# csi_tx_if_v2_1_VBUS2APB_WRAP_VBUSP_APB_CSI2TX_V2 register map
Vendor: Texas Instruments
Peripheral module from a debugger description file (folder J721S2).
Registers are 32-bit, read-write, reset 0x0 unless marked. A register's access mark holds for its fields unless they carry their own. Offsets are as the file gives them; lines under a group give offsets from that group; [hi:lo] are bit positions; {n}, {i} and the like mark numbered series; 'fields as' and 'values as' point back to an identical list; <NAME> marks a mode.

## csi_tx_if_v2_1_VBUS2APB_WRAP_VBUSP_APB_CSI2TX_V2
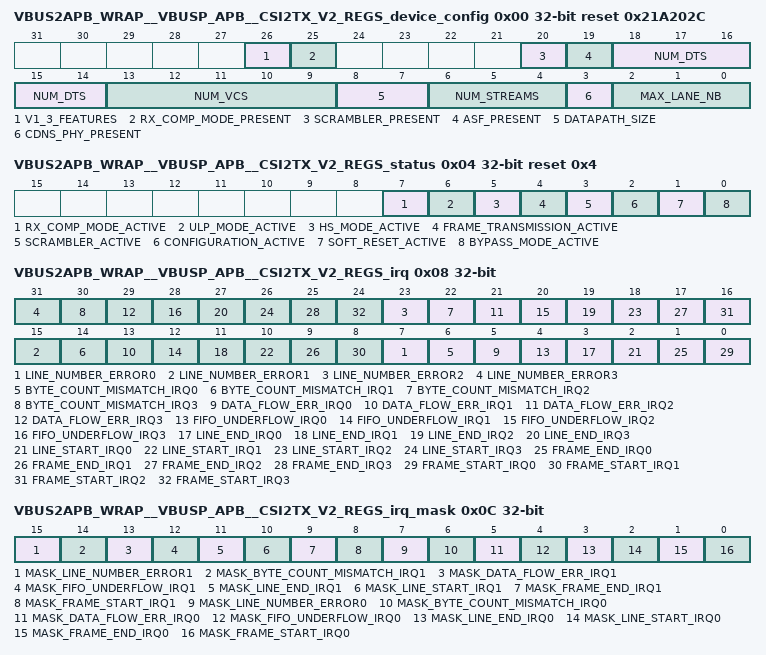
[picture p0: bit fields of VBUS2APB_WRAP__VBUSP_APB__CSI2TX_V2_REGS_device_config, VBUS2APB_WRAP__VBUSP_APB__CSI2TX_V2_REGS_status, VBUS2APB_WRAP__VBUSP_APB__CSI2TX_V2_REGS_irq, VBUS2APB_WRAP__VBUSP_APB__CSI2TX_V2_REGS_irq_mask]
0x00 VBUS2APB_WRAP__VBUSP_APB__CSI2TX_V2_REGS_device_config ro reset 0x21A202C — CSI-2 Transmitter Device Configuration Register
  [26] V1_3_FEATURES — : 1=CSI-2 v1.3 features only, 0=v2.1 features available
  [25] RX_COMP_MODE_PRESENT — RX Compatibility Mode: 1=implemented
  [20] SCRAMBLER_PRESENT — Scrambler: 1=implemented
  [19] ASF_PRESENT — Automotive Safety Features: 1=implemented
  [18:14] NUM_DTS — Number of Datatypes supported 8 or 16 only
  [13:9] NUM_VCS — Number of Virtual Channels supported 4 or 16 only
  [8:7] DATAPATH_SIZE — Internal datapath width 00: 32-bit.
  [6:4] NUM_STREAMS — Number of Stream interfaces 1, 2, or 4 only using direct encoding
  [3] CDNS_PHY_PRESENT — Cadence D-PHY present 1 = Yes
  [2:0] MAX_LANE_NB — Max Number of Lanes [1-4]
0x04 VBUS2APB_WRAP__VBUSP_APB__CSI2TX_V2_REGS_status ro reset 0x4 — CSI-2 Transmitter Status Register
  [7] RX_COMP_MODE_ACTIVE — RX Compatibility Mode Active Flag. When HIGH this bit indicates that RX Compatibility Mode is enabled.
  [6] ULP_MODE_ACTIVE — Ultra Low Power Mode Active Flag When HIGH this bit indicates that Ultra Low Power mode is active.
  [5] HS_MODE_ACTIVE — High Speed Mode Active Flag When HIGH this bit indicates that High Speed mode is active.
  [4] FRAME_TRANSMISSION_ACTIVE — Frame Transmission Active Flag When HIGH this bit indicates that frame transmission is active.
  [3] SCRAMBLER_ACTIVE — Scrambler Active Flag. When HIGH this bit indicates that the scrambler is enabled.
  [2] CONFIGURATION_ACTIVE — Configuration Mode Active Flag When HIGH this bit indicates that the CSI2TX module is in the configuration mode.
  [1] SOFT_RESET_ACTIVE — Soft Reset Active Flag When HIGH this bit indicates that soft reset is active.
  [0] BYPASS_MODE_ACTIVE — Bypass Mode Active Flag When HIGH this bit indicates that bypass mode is active.
0x08 VBUS2APB_WRAP__VBUSP_APB__CSI2TX_V2_REGS_irq access not given — CSI-2 Transmitter Interrupt Register. Write '1' to clear
  [8n+7] LINE_NUMBER_ERROR{n} (n=0..3) — Pixel IF {n} Line Number Error Flag - When HIGH this bit indicates that a line number error occurred. (access R/W1TC)
  [8n+6] BYTE_COUNT_MISMATCH_IRQ{n} (n=0..3) — Pixel IF {n} Byte Count Mismatch Flag - When HIGH this bit indicates that a byte count mismatch occurred. (access R/W1TC)
  [8n+5] DATA_FLOW_ERR_IRQ{n} (n=0..3) — Pixel IF {n} Data Flow Error Flag - When HIGH this bit indicates that data flow error has occurred, caused by the Frame/Line valid being asserted when the D-PHY is not ready. (access R/W1TC)
  [8n+4] FIFO_UNDERFLOW_IRQ{n} (n=0..3) — Pixel IF {n} FIFO Underflow Flag - When HIGH this bit indicates that at least one internal FIFO underflow occurred. (access R/W1TC)
  [8n+3] LINE_END_IRQ{n} (n=0..3) — Pixel IF {n} Line End Flag - When HIGH this bit indicates that a line end occurred. (access R/W1TC)
  [8n+2] LINE_START_IRQ{n} (n=0..3) — Pixel IF {n} Line Start Flag - When HIGH this bit indicates that a line start occurred. (access R/W1TC)
  [8n+1] FRAME_END_IRQ{n} (n=0..3) — Pixel IF {n} Frame End Flag - When HIGH this bit indicates that a frame end occurred. (access R/W1TC)
  [8n] FRAME_START_IRQ{n} (n=0..3) — Pixel IF {n} Frame Start Flag - When HIGH this bit indicates that a frame start occurred. (access R/W1TC)
0x0C VBUS2APB_WRAP__VBUSP_APB__CSI2TX_V2_REGS_irq_mask — CSI-2 Transmitter Interrupt Mask Register. In ASF configurations this register is parity protected.
  [15] MASK_LINE_NUMBER_ERROR1 — Pixel IF 1 Line Number Error Mask - Writing 1 to this bit enables interrupt generation from the line_number_error_irq bit.
  [14] MASK_BYTE_COUNT_MISMATCH_IRQ1 — Pixel IF 1 Byte Count Mismatch Mask - Writing 1 to this bit enables interrupt generation from the byte_count_mismatch_irq bit.
  [13] MASK_DATA_FLOW_ERR_IRQ1 — Pixel IF 1 Data Flow Error Mask - Writing 1 to this bit enables interrupt generation from the data_flow_err_irq bit.
  [12] MASK_FIFO_UNDERFLOW_IRQ1 — Pixel IF 1 FIFO Underflow Mask - Writing 1 to this bit enables interrupt generation from the fifo_underflow_irq bit.
  [11] MASK_LINE_END_IRQ1 — Pixel IF 1 Line End Mask - Writing 1 to this bit enables interrupt generation from the line_en_irq bit.
  [10] MASK_LINE_START_IRQ1 — Pixel IF 1 Line Start Mask - Writing 1 to this bit enables interrupt generation from the line_start_irq bit.
  [9] MASK_FRAME_END_IRQ1 — Pixel IF 1 Frame End Mask - Writing 1 to this bit enables interrupt generation from the frame_end_irq bit.
  [8] MASK_FRAME_START_IRQ1 — Pixel IF 1 Frame Start Mask - Writing 1 to this bit enables interrupt generation from the frame_start_irq bit.
  [7] MASK_LINE_NUMBER_ERROR0 — Pixel IF 0 Line Number Error Mask - Writing 1 to this bit enables interrupt generation from the line_number_error_irq bit.
  [6] MASK_BYTE_COUNT_MISMATCH_IRQ0 — Pixel IF 0 Byte Count Mismatch Mask - Writing 1 to this bit enables interrupt generation from the byte_count_mismatch_irq bit.
  [5] MASK_DATA_FLOW_ERR_IRQ0 — Pixel IF 0 Data Flow Error Mask - Writing 1 to this bit enables interrupt generation from the data_flow_err_irq bit.
  [4] MASK_FIFO_UNDERFLOW_IRQ0 — Pixel IF 0 FIFO Underflow Mask - Writing 1 to this bit enables interrupt generation from the fifo_underflow_irq bit.
  [3] MASK_LINE_END_IRQ0 — Pixel IF 0 Line End Mask - Writing 1 to this bit enables interrupt generation from the line_en_irq bit.
  [2] MASK_LINE_START_IRQ0 — Pixel IF 0 Line Start Mask - Writing 1 to this bit enables interrupt generation from the line_start_irq bit.
  [1] MASK_FRAME_END_IRQ0 — Pixel IF 0 Frame End Mask - Writing 1 to this bit enables interrupt generation from the frame_end_irq bit.
  [0] MASK_FRAME_START_IRQ0 — Pixel IF 0 Frame Start Mask - Writing 1 to this bit enables interrupt generation from the frame_start_irq bit.
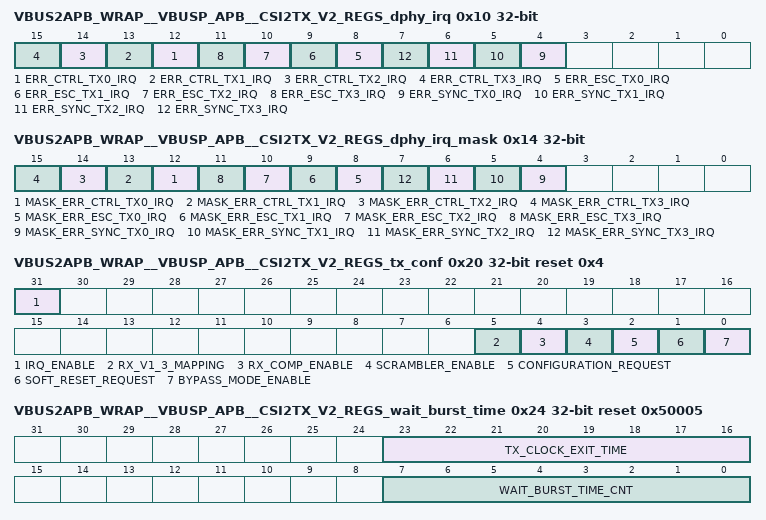
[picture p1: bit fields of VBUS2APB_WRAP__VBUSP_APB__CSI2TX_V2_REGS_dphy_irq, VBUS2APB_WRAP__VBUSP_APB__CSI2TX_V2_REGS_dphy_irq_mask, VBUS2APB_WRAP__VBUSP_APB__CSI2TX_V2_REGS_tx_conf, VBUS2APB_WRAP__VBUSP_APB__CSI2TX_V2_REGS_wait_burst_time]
0x10 VBUS2APB_WRAP__VBUSP_APB__CSI2TX_V2_REGS_dphy_irq access not given — D-PHY Transmitter Interrupt Status. Level sensitive interrupt bits driven by D-PHY signal pins. Write 1 to clear
  [n+12] ERR_CTRL_TX{n}_IRQ (n=0..3) — D-PHY Transmitter Lane {n} ERR_CONTROL_IRQ (access R/W1TC)
  [n+8] ERR_ESC_TX{n}_IRQ (n=0..3) — D-PHY Transmitter Lane {n} ERR_ESC_IRQ (access R/W1TC)
  [n+4] ERR_SYNC_TX{n}_IRQ (n=0..3) — D-PHY Transmitter Lane {n} ERR_SYNC_ESC_IRQ (access R/W1TC)
0x14 VBUS2APB_WRAP__VBUSP_APB__CSI2TX_V2_REGS_dphy_irq_mask — D-PHY Transmitter Interrupt Mask. Writing '1' to any bit enables interrupt generation when interrupt source signal is set and interrupts are enabled. In ASF configurations this register is parity protected.
  [n+12] MASK_ERR_CTRL_TX{n}_IRQ (n=0..3) — D-PHY Transmitter Mask Lane {n} ERR_CONTROL_IRQ
  [n+8] MASK_ERR_ESC_TX{n}_IRQ (n=0..3) — D-PHY Transmitter Mask Lane {n} ERR_ESC_IRQ
  [n+4] MASK_ERR_SYNC_TX{n}_IRQ (n=0..3) — D-PHY Transmitter Mask Lane {n} ERR_SYNC_ESC_IRQ
0x20 VBUS2APB_WRAP__VBUSP_APB__CSI2TX_V2_REGS_tx_conf reset 0x4 — CSI-2 Transmitter Configuration Register. In ASF configurations this register is parity protected.
  [31] IRQ_ENABLE — Interrupt Enable - Writing 1 to this bit enables interrupts.
  [5] RX_V1_3_MAPPING — RX v1.3 Mapping Enable - Writing 1 to this bit make the TX Controller use pixel mappings for 8-bit data types which match that of the Cadence CSI-2 RX v1.3 Controller. This includes RAW8, Null, Blanking, Embedded, User Defined and Generic Long Packet data types. This bit is only available if RX_COMP_MODE is configured.
  [4] RX_COMP_ENABLE — RX Compatibility Mode Enable - Writing 1 to this bit enables RX Compatibility Mode.
  [3] SCRAMBLER_ENABLE — Scrambler Enable - Writing 1 to this bit enables scrambling on the ppi tx data bus.
  [2] CONFIGURATION_REQUEST — Configuration Request - Writing 1 to this bit enables configuration mode.
  [1] SOFT_RESET_REQUEST — Soft Reset Request - Writing 1 to this bit enables soft reset.
  [0] BYPASS_MODE_ENABLE — Bypass Mode - Enable Writing 1 to this bit enables bypass mode.
0x24 VBUS2APB_WRAP__VBUSP_APB__CSI2TX_V2_REGS_wait_burst_time reset 0x50005 — CSI-2 Transmitter D-PHY Wait Time Configuration Register. In ASF configurations this register is parity protected.
  [23:16] TX_CLOCK_EXIT_TIME — Tx clock exit time - Number of ppi_tx_word_hs_clk cycles corresponding to the HS clock exit time.
  [7:0] WAIT_BURST_TIME_CNT — Wait Burst Time - Number of ppi_tx_word_hs_clk cycles corresponding to the inter HS burst gap.
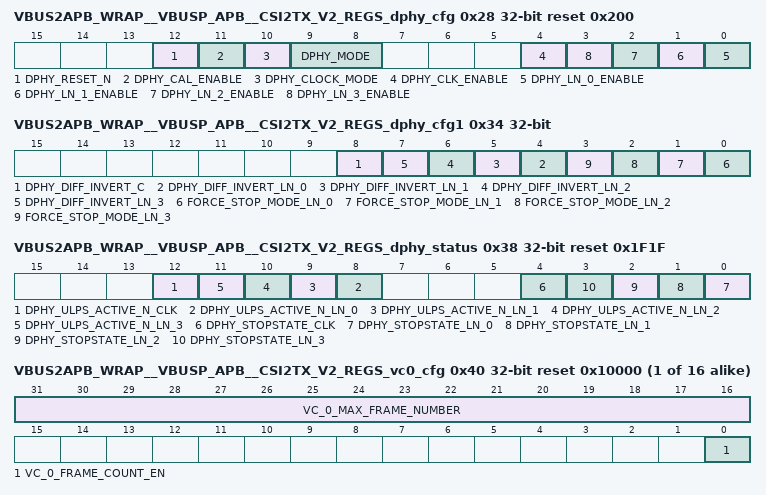
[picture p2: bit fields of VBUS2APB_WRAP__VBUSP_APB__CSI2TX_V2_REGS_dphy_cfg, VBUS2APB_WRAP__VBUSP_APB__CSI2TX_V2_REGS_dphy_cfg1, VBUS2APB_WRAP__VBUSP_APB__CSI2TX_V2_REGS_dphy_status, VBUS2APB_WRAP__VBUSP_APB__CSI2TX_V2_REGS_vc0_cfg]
0x28 VBUS2APB_WRAP__VBUSP_APB__CSI2TX_V2_REGS_dphy_cfg reset 0x200 — CSI-2 Transmitter D-PHY Lane Enable Configuration Register. In ASF configurations this register is parity protected.
  [12] DPHY_RESET_N — D-PHY Reset - Active low reset for D-PHY.
  [11] DPHY_CAL_ENABLE — D-PHY Calibration Enable. Enables calibration for D-PHY speeds over 1.5G.
  [10] DPHY_CLOCK_MODE — D-PHY Clock Mode. Select the D-PHY Clock Lane mode 0: Continuous 1: Non Continuous
  [9:8] DPHY_MODE — D-PHY Mode. Select the D-PHY clock mode during Non Continuous operation 00: Ultra Low Power 01: High Speed 10: Low Power Stop State 11: Reserved
  [4] DPHY_CLK_ENABLE — D-PHY Clock Lane - Active high enable for D-PHY clock lane.
  [n] DPHY_LN_{n}_ENABLE (n=0..3) — D-PHY Lane {n} Enable - Active high enable for D-PHY data lane 0.
0x2C VBUS2APB_WRAP__VBUSP_APB__CSI2TX_V2_REGS_dphy_clk_wakeup reset 0x4E20 — CSI-2 Transmitter D-PHY Clock Lane Wakeup Time Configuration Register. In ASF configurations this register is parity protected.
  [15:0] ULPS_CLK_LANE_WAKEUP — D-PHY clock lane wakeup time in ppi_tx_esc_clk cycles.
0x30 VBUS2APB_WRAP__VBUSP_APB__CSI2TX_V2_REGS_dphy_ulps_wakeup reset 0x4E20 — CSI-2 Transmitter D-PHY Data Lane Wakeup Time Configuration Register. In ASF configurations this register is parity protected.
  [15:0] ULPS_DATA_LANE_WAKEUP — D-PHY data lane wakeup time in in ppi_tx_esc_clk cycles.
0x34 VBUS2APB_WRAP__VBUSP_APB__CSI2TX_V2_REGS_dphy_cfg1 — D-PHY Transmitter Configuration. In ASF configurations this register is parity protected.
  [8] DPHY_DIFF_INVERT_C — D-PHY Transmitter invert differential pair on TX Clock Lane
  [n+4] DPHY_DIFF_INVERT_LN_{n} (n=0..3) — D-PHY Transmitter invert differential pair on TX Data Lane {n}.
  [n] FORCE_STOP_MODE_LN_{n} (n=0..3) — D-PHY Transmitter FORCE_STOP_MODE TX Data Lane {n}.
0x38 VBUS2APB_WRAP__VBUSP_APB__CSI2TX_V2_REGS_dphy_status ro reset 0x1F1F — D-PHY Transmitter Status.
  [12] DPHY_ULPS_ACTIVE_N_CLK — D-PHY Transmitter ULPS_ACTIVE_N Clock Lane Status.
  [n+8] DPHY_ULPS_ACTIVE_N_LN_{n} (n=0..3) — D-PHY Transmitter ULPS_ACTIVE_N Data Lane {n} Status.
  [4] DPHY_STOPSTATE_CLK — D-PHY Transmitter STOP_STATE Clock Lane Status.
  [n] DPHY_STOPSTATE_LN_{n} (n=0..3) — D-PHY Transmitter STOP_STATE Data Lane {n} Status.
{0x40+4i} VBUS2APB_WRAP__VBUSP_APB__CSI2TX_V2_REGS_vc{i}_cfg reset 0x10000 (i=0..15) — CSI-2 Transmitter Virtual Channel {i} Configuration Register. In ASF configurations this register is parity protected.
  [31:16] VC_{i}_MAX_FRAME_NUMBER — Max Frame Number - Maximum number of frames on Virtual Channel {i}.
  [0] VC_{i}_FRAME_COUNT_EN — Frame Count Enable - Writing 1 to this bit enables frame count on Virtual Channel {i}.
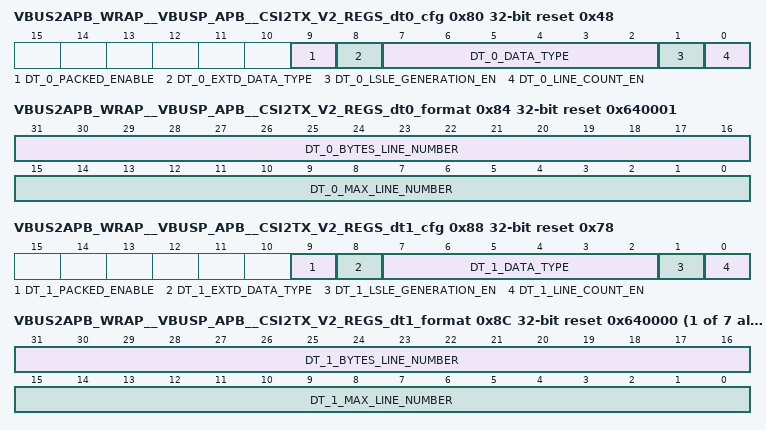
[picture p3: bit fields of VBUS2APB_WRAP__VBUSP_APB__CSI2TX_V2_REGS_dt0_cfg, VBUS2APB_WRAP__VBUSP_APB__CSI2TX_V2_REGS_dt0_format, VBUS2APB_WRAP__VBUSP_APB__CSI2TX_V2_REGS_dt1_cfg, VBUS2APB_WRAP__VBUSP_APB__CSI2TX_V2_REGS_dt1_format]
0x80 VBUS2APB_WRAP__VBUSP_APB__CSI2TX_V2_REGS_dt0_cfg reset 0x48 — CSI-2 Transmitter Data Type 0 Configuration Register with pixel_dt_sel[:] = 0. In ASF configurations this register is parity protected.
  [9] DT_0_PACKED_ENABLE — Packed Enable - data stream is prepacked in to 32-bit words on the pixel interface, the data is sent with the defined Data Type 0 with pixel_dt_sel[:] = 0. This bit is also used for quad pixel 8-bit data types.
  [8] DT_0_EXTD_DATA_TYPE — Extended Data Type - Type of data on Data Type 0 with pixel_dt_sel[:] = 0.
  [7:2] DT_0_DATA_TYPE — Data Type - Type of data on Data Type 0 with pixel_dt_sel[:] = 0. Default ED [0x12]
  [1] DT_0_LSLE_GENERATION_EN — Line Start And Line End Short Packet Generation Enable - Writing 1 to this bit enables Line Start and Line End generation on Data Type 0.
  [0] DT_0_LINE_COUNT_EN — Line Count Enable - Writing 1 to this bit enables line count on Data Type 0.
0x84 VBUS2APB_WRAP__VBUSP_APB__CSI2TX_V2_REGS_dt0_format reset 0x640001 — CSI-2 Transmitter Data Type 0 Format Register. In ASF configurations this register is parity protected.
  [31:16] DT_0_BYTES_LINE_NUMBER — Bytes Per Line - Bytes per line on Data Type 0 with pixel_dt_sel[:] = 0.
  [15:0] DT_0_MAX_LINE_NUMBER — Max Line Number - Maximum number of lines on Data Type 0 with pixel_dt_sel[:] = 0.
0x88 VBUS2APB_WRAP__VBUSP_APB__CSI2TX_V2_REGS_dt1_cfg reset 0x78 — CSI-2 Transmitter Data Type 1 Configuration Register with pixel_dt_sel[:] = 1. In ASF configurations this register is parity protected.
  [9] DT_1_PACKED_ENABLE — Packed Enable - data stream is prepacked in to 32-bit words on the pixel interface, the data is sent with the defined Data Type 1 with pixel_dt_sel[:] = 1. This bit is also used for quad pixel 8-bit data types.
  [8] DT_1_EXTD_DATA_TYPE — Extended Data Type - Type of data on Data Type 1 with pixel_dt_sel[:] = 1.
  [7:2] DT_1_DATA_TYPE — Data Type - Type of data on Data Type 1 with pixel_dt_sel[:] = 1. Default YUV422 8bit [0x1E]
  [1] DT_1_LSLE_GENERATION_EN — Line Start And Line End Short Packet Generation Enable - Writing 1 to this bit enables Line Start and Line End generation on Data Type 1.
  [0] DT_1_LINE_COUNT_EN — Line Count Enable - Writing 1 to this bit enables line count on Data Type 1.
{0x84+8i} VBUS2APB_WRAP__VBUSP_APB__CSI2TX_V2_REGS_dt{i}_format reset 0x640000 (i=1..7) — CSI-2 Transmitter Data Type {i} Format Register. In ASF configurations this register is parity protected.
  [31:16] DT_{i}_BYTES_LINE_NUMBER — Bytes Per Line - Bytes per line on Data Type {i} with pixel_dt_sel[:] = {i}.
  [15:0] DT_{i}_MAX_LINE_NUMBER — Max Line Number - Maximum number of lines on Data Type {i} with pixel_dt_sel[:] = {i}.
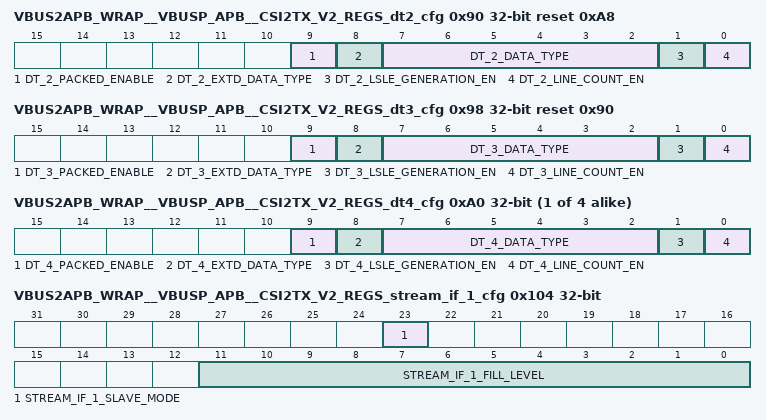
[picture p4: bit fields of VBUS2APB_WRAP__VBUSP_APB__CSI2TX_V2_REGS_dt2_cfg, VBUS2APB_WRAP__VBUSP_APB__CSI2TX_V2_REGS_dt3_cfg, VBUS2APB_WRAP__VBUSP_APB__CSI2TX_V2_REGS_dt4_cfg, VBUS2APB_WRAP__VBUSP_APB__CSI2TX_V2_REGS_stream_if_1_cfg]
0x90 VBUS2APB_WRAP__VBUSP_APB__CSI2TX_V2_REGS_dt2_cfg reset 0xA8 — CSI-2 Transmitter Data Type 2 Configuration Register with pixel_dt_sel[:] = 2. In ASF configurations this register is parity protected.
  [9] DT_2_PACKED_ENABLE — Packed Enable - data stream is prepacked in to 32-bit words on the pixel interface, the data is sent with the defined Data Type 2 with pixel_dt_sel[:] = 2. This bit is also used for quad pixel 8-bit data types.
  [8] DT_2_EXTD_DATA_TYPE — Extended Data Type - Type of data on Data Type 2 with pixel_dt_sel[:] = 2.
  [7:2] DT_2_DATA_TYPE — Data Type - Type of data on Data Type 2 with pixel_dt_sel[:] = 2. Default RAW8 [0x2A]
  [1] DT_2_LSLE_GENERATION_EN — Line Start And Line End Short Packet Generation Enable - Writing 1 to this bit enables Line Start and Line End generation on Data Type 2.
  [0] DT_2_LINE_COUNT_EN — Line Count Enable - Writing 1 to this bit enables line count on Data Type 2.
0x98 VBUS2APB_WRAP__VBUSP_APB__CSI2TX_V2_REGS_dt3_cfg reset 0x90 — CSI-2 Transmitter Data Type 3 Configuration Register with pixel_dt_sel[:] = 3. In ASF configurations this register is parity protected.
  [9] DT_3_PACKED_ENABLE — Packed Enable - data stream is prepacked in to 32-bit words on the pixel interface, the data is sent with the defined Data Type 3 with pixel_dt_sel[:] = 3. This bit is also used for quad pixel 8-bit data types.
  [8] DT_3_EXTD_DATA_TYPE — Extended Data Type - Type of data on Data Type 3 with pixel_dt_sel[:] = 3.
  [7:2] DT_3_DATA_TYPE — Data Type - Type of data on Data Type 3 with pixel_dt_sel[:] = 3. Default RGB888 [0x24]
  [1] DT_3_LSLE_GENERATION_EN — Line Start And Line End Short Packet Generation Enable - Writing 1 to this bit enables Line Start and Line End generation on Data Type 3.
  [0] DT_3_LINE_COUNT_EN — Line Count Enable - Writing 1 to this bit enables line count on Data Type 3.
{0x80+8i} VBUS2APB_WRAP__VBUSP_APB__CSI2TX_V2_REGS_dt{i}_cfg (i=4..7) — CSI-2 Transmitter Data Type {i} Configuration Register with pixel_dt_sel[:] = {i}. In ASF configurations this register is parity protected.
  [9] DT_{i}_PACKED_ENABLE — Packed Enable - data stream is prepacked in to 32-bit words on the pixel interface, the data is sent with the defined Data Type {i} with pixel_dt_sel[:] = {i}. This bit is also used for quad pixel 8-bit data types.
  [8] DT_{i}_EXTD_DATA_TYPE — Extended Data Type - Type of data on Data Type {i} with pixel_dt_sel[:] = {i}.
  [7:2] DT_{i}_DATA_TYPE — Data Type - Type of data on Data Type {i} with pixel_dt_sel[:] = {i}.
  [1] DT_{i}_LSLE_GENERATION_EN — Line Start And Line End Short Packet Generation Enable - Writing 1 to this bit enables Line Start and Line End generation on Data Type {i}.
  [0] DT_{i}_LINE_COUNT_EN — Line Count Enable - Writing 1 to this bit enables line count on Data Type {i}.
0x100 VBUS2APB_WRAP__VBUSP_APB__CSI2TX_V2_REGS_stream_if_0_cfg — CSI-2 Stream 0 Configuration Register. In ASF configurations this register is parity protected.
  [11:0] STREAM_IF_0_FILL_LEVEL — Fill Level - Minimum number of packed 32 words loaded into the stream fifo before Tx will start for Stream if 0.
0x104 VBUS2APB_WRAP__VBUSP_APB__CSI2TX_V2_REGS_stream_if_1_cfg — CSI-2 Stream 1 Configuration Register. In ASF configurations this register is parity protected.
  [23] STREAM_IF_1_SLAVE_MODE — Stream Slave Mode suppresses frame start/end packets in stream 1. To be used when DT interleving is required in the same VC. NOTE: the stream must then be paired with stream O as the master on the StreamIF
  [11:0] STREAM_IF_1_FILL_LEVEL — Fill Level - Minimum number of packed 32 words loaded into the stream fifo before Tx will start for Stream if 1.
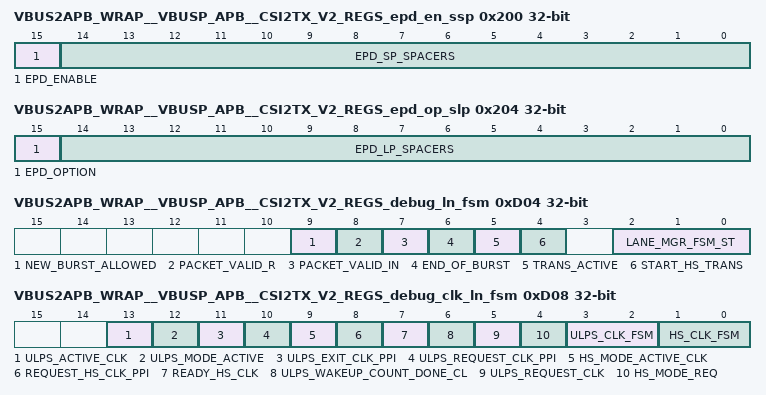
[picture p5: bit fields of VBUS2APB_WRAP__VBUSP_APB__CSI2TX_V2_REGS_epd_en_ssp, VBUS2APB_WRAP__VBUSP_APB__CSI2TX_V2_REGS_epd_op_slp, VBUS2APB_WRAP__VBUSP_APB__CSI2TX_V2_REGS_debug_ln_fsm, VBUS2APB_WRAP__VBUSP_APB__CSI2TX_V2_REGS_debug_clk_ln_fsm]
0x200 VBUS2APB_WRAP__VBUSP_APB__CSI2TX_V2_REGS_epd_en_ssp — CSI-2 Transmitter EPD Enable and Short Packet Spacers Register Mandatory register in the CSI-2 v2.x specification. In ASF configurations this register is parity protected.
  [15] EPD_ENABLE — EPD enable. Set high to enable EPD operation.
  [14:0] EPD_SP_SPACERS — EPD Short Packet Spacers: EPD Option 1: Minimum number of Spacer Bytes per Lane following a Short Packet. EPD Option 2: Fixed number of Spacer Bytes per Lane following a Short Packet.
0x204 VBUS2APB_WRAP__VBUSP_APB__CSI2TX_V2_REGS_epd_op_slp — CSI-2 Transmitter EPD Option and Long Packet Spacers Register Mandatory register in the CSI-2 v2.x specification. In ASF configurations this register is parity protected.
  [15] EPD_OPTION — EPD Option. 1'b0: D-PHY EPD Option 1 1'b1: D-PHY EPD Option 2
  [14:0] EPD_LP_SPACERS — EPD Long Packet Spacers: EPD Option 1: Minimum number of Spacer Bytes per Lane following a Long Packet. EPD Option 2: Fixed number of Spacer Bytes per Lane following a Long Packet.
0x208 VBUS2APB_WRAP__VBUSP_APB__CSI2TX_V2_REGS_epd_clkidlehs_min reset 0x10 — CSI-2 Transmitter EPD Minimum HS Clock Idle Time Register In ASF configurations this register is parity protected.
  [15:0] EPD_OPTION1_CLKIDLEHS_MIN — For LRTE EPD Option 1, this sets the minimum number of pclk cycles required to meet the D-PHY timing requirement for THS-IDLE-CLKHS0.
0xD00 VBUS2APB_WRAP__VBUSP_APB__CSI2TX_V2_REGS_debug_cfg — CSI-2 Transmitter Debug Enable Register. In ASF configurations this register is parity protected.
  [0] DBG_EN — Debug Enable. This bit enables debug when high. If low then other DEBUG registers read 0.
0xD04 VBUS2APB_WRAP__VBUSP_APB__CSI2TX_V2_REGS_debug_ln_fsm ro — Debug Register for Lane FSM.
  [9] NEW_BURST_ALLOWED — Lane Mangement FSM. New burst allowed - WAIT_BURST_TIME expired
  [8] PACKET_VALID_R — Lane Mangement FSM. Valid packet in packet register
  [7] PACKET_VALID_IN — Lane Mangement FSM. Valid packet at input
  [6] END_OF_BURST — Lane Mangement FSM. End of High speed burst
  [5] TRANS_ACTIVE — Lane Mangement FSM. HS transmission active
  [4] START_HS_TRANS — Lane Mangement FSM. HS transmission ready
  [2:0] LANE_MGR_FSM_ST — Lane Mangement FSM. State of Lane Management FSM
0xD08 VBUS2APB_WRAP__VBUSP_APB__CSI2TX_V2_REGS_debug_clk_ln_fsm ro — Debug Register for Clock Lane FSM
  [13] ULPS_ACTIVE_CLK — Clock Lane FSM. ULPS active from D-PHY
  [12] ULPS_MODE_ACTIVE — Clock Lane FSM. ULPS mode active
  [11] ULPS_EXIT_CLK_PPI — Clock Lane FSM. ULPS EXIT Request to D-PHY
  [10] ULPS_REQUEST_CLK_PPI — Clock Lane FSM. ULPS request to D-PHY
  [9] HS_MODE_ACTIVE_CLK — Clock Lane FSM. High speed mode active
  [8] REQUEST_HS_CLK_PPI — Clock Lane FSM. High speed clock request
  [7] READY_HS_CLK — Clock Lane FSM. High speed clock active from D-PHY
  [6] ULPS_WAKEUP_COUNT_DONE_CL — Clock Lane FSM. Clock lane ULPS wakeup counter expired
  [5] ULPS_REQUEST_CLK — Clock Lane FSM. Request ULPS mode
  [4] HS_MODE_REQ — Clock Lane FSM. Request High Speed mode
  [3:2] ULPS_CLK_FSM — Clock Lane FSM. State of ULPS control FSM.
  [1:0] HS_CLK_FSM — Clock Lane FSM. State of High Speed Clock FSM.
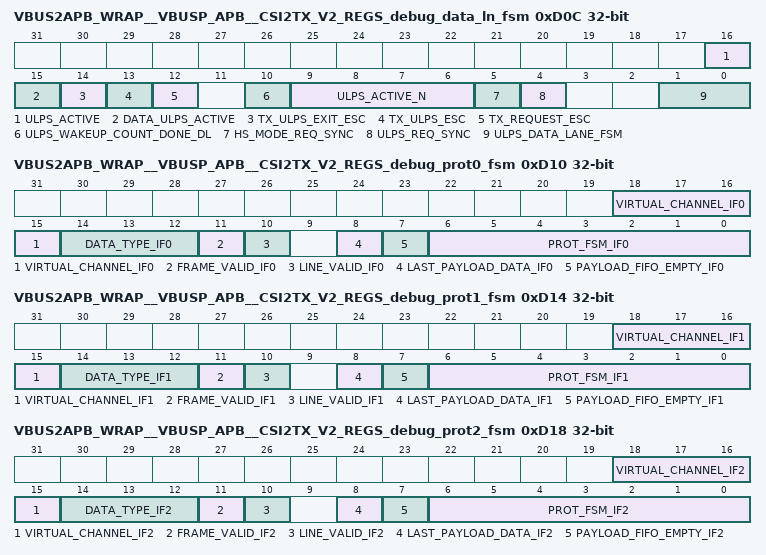
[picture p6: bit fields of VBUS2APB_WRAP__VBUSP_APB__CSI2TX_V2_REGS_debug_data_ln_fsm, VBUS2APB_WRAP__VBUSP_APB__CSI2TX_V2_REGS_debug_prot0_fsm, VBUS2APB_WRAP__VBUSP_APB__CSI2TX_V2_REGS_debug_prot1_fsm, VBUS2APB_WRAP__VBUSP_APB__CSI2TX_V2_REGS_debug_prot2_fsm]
0xD0C VBUS2APB_WRAP__VBUSP_APB__CSI2TX_V2_REGS_debug_data_ln_fsm ro — Debug Register for Data Lane FSM.
  [16] ULPS_ACTIVE — Data Lane FSM. Clock and data lane ULPS active
  [15] DATA_ULPS_ACTIVE — Debug Register for Data Lane FSM. Data lane ULPS active
  [14] TX_ULPS_EXIT_ESC — Data Lane FSM. Exit escape mode to D-PHY
  [13] TX_ULPS_ESC — Data Lane FSM. ULPS escape mode to D-PHY
  [12] TX_REQUEST_ESC — Data Lane FSM. Request escape mode to D-PHY
  [10] ULPS_WAKEUP_COUNT_DONE_DL — Data Lane FSM. Data Lane ULPS wakeup counter expired
  [9:6] ULPS_ACTIVE_N — Data Lane FSM. Data Lane ULPS active from D-PHY
  [5] HS_MODE_REQ_SYNC — Data Lane FSM. HS Mode request
  [4] ULPS_REQ_SYNC — Data Lane FSM. ULPS Request
  [1:0] ULPS_DATA_LANE_FSM — Data Lane FSM. State of Data Lane FSM FSM
0xD10 VBUS2APB_WRAP__VBUSP_APB__CSI2TX_V2_REGS_debug_prot0_fsm ro — Debug Register for Pixel IF0 Protocol FSM.
  [18:15] VIRTUAL_CHANNEL_IF0 — Pixel IF0 Protocol FSM. State of the top level Virtual Channel select signals State of the Virtual Channel[3:2] select signals when VCX enabled, otherwise '00' and state of the Virtual Channel[1:0]
  [14:12] DATA_TYPE_IF0 — Pixel IF0 Protocol FSM. State of the Data Type select signals
  [11] FRAME_VALID_IF0 — Pixel IF0 Protocol FSM. State of the Frame Valid signal
  [10] LINE_VALID_IF0 — Pixel IF0 Protocol FSM. State of the Line Valid signal
  [8] LAST_PAYLOAD_DATA_IF0 — Pixel IF0 Protocol FSM. Last payload data in long packet
  [7] PAYLOAD_FIFO_EMPTY_IF0 — Pixel IF0 Protocol FSM. Payload FIFO empty
  [6:0] PROT_FSM_IF0 — Pixel IF0 Protocol FSM. State of Protocol Control FSM
0xD14 VBUS2APB_WRAP__VBUSP_APB__CSI2TX_V2_REGS_debug_prot1_fsm ro — Debug Register for Pixel IF1 Protocol FSM. (Optional: Available when PIXEL_IF2 or 4)
  [18:15] VIRTUAL_CHANNEL_IF1 — Pixel IF1 Protocol FSM. State of the top level Virtual Channel select signals State of the Virtual Channel[3:2] select signals when VCX enabled, otherwise '00' and state of the Virtual Channel[1:0]
  [14:12] DATA_TYPE_IF1 — Pixel IF1 Protocol FSM. State of the Data Type select signals
  [11] FRAME_VALID_IF1 — Pixel IF1 Protocol FSM. State of the Frame Valid signal
  [10] LINE_VALID_IF1 — Pixel IF1 Protocol FSM. State of the Line Valid signal
  [8] LAST_PAYLOAD_DATA_IF1 — Pixel IF1 Protocol FSM. Last payload data in long packet
  [7] PAYLOAD_FIFO_EMPTY_IF1 — Pixel IF1 Protocol FSM. Payload FIFO empty
  [6:0] PROT_FSM_IF1 — Pixel IF1 Protocol FSM. State of Protocol Control FSM
0xD18 VBUS2APB_WRAP__VBUSP_APB__CSI2TX_V2_REGS_debug_prot2_fsm ro — Debug Register for Pixel IF2 Protocol FSM. (Optional: Available when PIXEL_IF4)
  [18:15] VIRTUAL_CHANNEL_IF2 — Pixel IF2 Protocol FSM. State of the top level Virtual Channel select signals State of the Virtual Channel[3:2] select signals when VCX enabled, otherwise '00' and state of the Virtual Channel[1:0]
  [14:12] DATA_TYPE_IF2 — Pixel IF2 Protocol FSM. State of the Data Type select signals
  [11] FRAME_VALID_IF2 — Pixel IF2 Protocol FSM. State of the Frame Valid signal
  [10] LINE_VALID_IF2 — Pixel IF2 Protocol FSM. State of the Line Valid signal
  [8] LAST_PAYLOAD_DATA_IF2 — Pixel IF2 Protocol FSM. Last payload data in long packet
  [7] PAYLOAD_FIFO_EMPTY_IF2 — Pixel IF2 Protocol FSM. Payload FIFO empty
  [6:0] PROT_FSM_IF2 — Pixel IF2 Protocol FSM. State of Protocol Control FSM
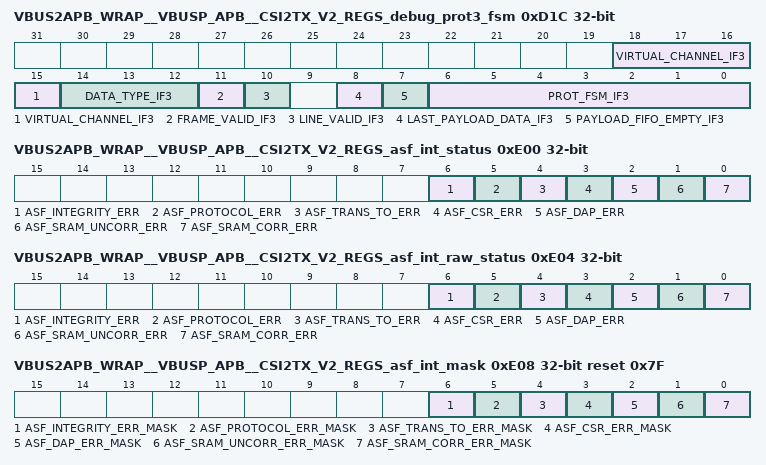
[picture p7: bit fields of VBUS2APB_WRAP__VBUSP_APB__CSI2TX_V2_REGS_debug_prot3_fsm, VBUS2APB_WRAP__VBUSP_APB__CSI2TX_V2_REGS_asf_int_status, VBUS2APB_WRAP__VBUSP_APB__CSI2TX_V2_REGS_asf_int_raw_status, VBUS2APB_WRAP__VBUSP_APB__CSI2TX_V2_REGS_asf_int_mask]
0xD1C VBUS2APB_WRAP__VBUSP_APB__CSI2TX_V2_REGS_debug_prot3_fsm ro — Debug Register for Pixel IF3 Protocol FSM. (Optional: Available when PIXEL_IF4)
  [18:15] VIRTUAL_CHANNEL_IF3 — Pixel IF3 Protocol FSM. State of the top level Virtual Channel select signals State of the Virtual Channel[3:2] select signals when VCX enabled, otherwise '00' and state of the Virtual Channel[1:0]
  [14:12] DATA_TYPE_IF3 — Pixel IF3 Protocol FSM. State of the Data Type select signals
  [11] FRAME_VALID_IF3 — Pixel IF3 Protocol FSM. State of the Frame Valid signal
  [10] LINE_VALID_IF3 — Pixel IF3 Protocol FSM. State of the Line Valid signal
  [8] LAST_PAYLOAD_DATA_IF3 — Pixel IF3 Protocol FSM. Last payload data in long packet
  [7] PAYLOAD_FIFO_EMPTY_IF3 — Pixel IF3 Protocol FSM. Payload FIFO empty
  [6:0] PROT_FSM_IF3 — Pixel IF3 Protocol FSM. State of Protocol Control FSM
0xDF8 VBUS2APB_WRAP__VBUSP_APB__CSI2TX_V2_REGS_test_generic_status ro — GPIO - Generic test status register that read primary inputs: test_generic_status
  [15:0] STATUS — Test status - Directly reflects, after resynchronisation into the pclk domain, the state of 'test_generic_status' primary inputs.
0xDFC VBUS2APB_WRAP__VBUSP_APB__CSI2TX_V2_REGS_test_generic_ctrl — GPIO - Generic test control register that controls primary outputs: test_generic_ctrl. In ASF configurations this register is parity protected.
  [15:0] CTRL — Test control - Directly controls primary outputs 'test_generic_ctrl'
0xE00 VBUS2APB_WRAP__VBUSP_APB__CSI2TX_V2_REGS_asf_int_status access not given — ASF Interrupt Status Register. This register indicates the source of ASF interrupts. The corresponding bit in the mask register must be clear for a bit to be set. If any bit is set in this register the asf_int_fatal or asf_int_nonfatal signal will be asserted. Writing to either raw or masked status registers, clear both registers. For test purposes, trigger signal interrupt event by writing to the ASF interrupt status test register.
  [6] ASF_INTEGRITY_ERR — Integrity error interrupt (access R/W1TC)
  [5] ASF_PROTOCOL_ERR — Protocol error interrupt (access R/W1TC)
  [4] ASF_TRANS_TO_ERR — Transaction timeouts error interrupt (access R/W1TC)
  [3] ASF_CSR_ERR — Configuration and status registers error interrupt (access R/W1TC)
  [2] ASF_DAP_ERR — Data and address paths parity error interrupt (access R/W1TC)
  [1] ASF_SRAM_UNCORR_ERR — SRAM uncorrectable error interrupt (access R/W1TC)
  [0] ASF_SRAM_CORR_ERR — SRAM correctable error interrupt (access R/W1TC)
0xE04 VBUS2APB_WRAP__VBUSP_APB__CSI2TX_V2_REGS_asf_int_raw_status access not given — ASF Interrupt Raw Status Register. A bit set in this raw register indicates a source of ASF fault in the corresponding feature. Writing to either raw or masked status registers, clear both registers. For test purposes, trigger signal interrupt event by writing to the ASF interrupt status test register.
  fields as VBUS2APB_WRAP__VBUSP_APB__CSI2TX_V2_REGS_asf_int_status
0xE08 VBUS2APB_WRAP__VBUSP_APB__CSI2TX_V2_REGS_asf_int_mask access not given reset 0x7F — The ASF interrupt mask register indicating which interrupt bits in the ASF interrupt status register are masked. All bits are set at reset. Clear the individual bit to enable the corresponding interrupt.
  [6] ASF_INTEGRITY_ERR_MASK rw — Mask bit for integrity error interrupt
  [5] ASF_PROTOCOL_ERR_MASK rw — Mask bit for protocol error interrupt.
  [4] ASF_TRANS_TO_ERR_MASK rw — Mask bit for transaction timeouts error interrupt.
  [3] ASF_CSR_ERR_MASK rw — Mask bit for configuration and status registers error interrupt.
  [2] ASF_DAP_ERR_MASK rw — Mask bit for data and address paths parity error interrupt.
  [1] ASF_SRAM_UNCORR_ERR_MASK rw — Mask bit for SRAM uncorrectable error interrupt.
  [0] ASF_SRAM_CORR_ERR_MASK rw — Mask bit for SRAM correctable error interrupt.
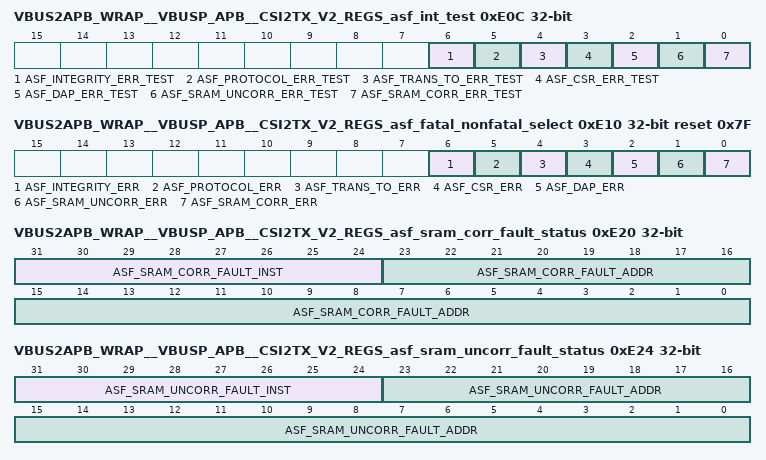
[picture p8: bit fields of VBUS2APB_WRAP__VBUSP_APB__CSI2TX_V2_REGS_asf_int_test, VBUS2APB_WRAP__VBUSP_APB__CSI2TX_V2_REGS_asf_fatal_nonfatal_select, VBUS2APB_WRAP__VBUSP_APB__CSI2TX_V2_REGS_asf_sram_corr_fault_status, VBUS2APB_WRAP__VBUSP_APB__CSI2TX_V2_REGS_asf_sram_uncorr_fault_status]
0xE0C VBUS2APB_WRAP__VBUSP_APB__CSI2TX_V2_REGS_asf_int_test access not given — The ASF interrupt test register emulate hardware even. Write one to individual bit to trigger single event in (masked and raw) status registers according to mask and will generate interrupt accordingly.
  [6] ASF_INTEGRITY_ERR_TEST wo — Test bit for integrity error interrupt
  [5] ASF_PROTOCOL_ERR_TEST wo — Test bit for protocol error interrupt.
  [4] ASF_TRANS_TO_ERR_TEST wo — Test bit for transaction timeouts error interrupt.
  [3] ASF_CSR_ERR_TEST wo — Test bit for configuration and status registers error interrupt.
  [2] ASF_DAP_ERR_TEST wo — Test bit for data and address paths parity error interrupt.
  [1] ASF_SRAM_UNCORR_ERR_TEST wo — Test bit for SRAM uncorrectable error interrupt.
  [0] ASF_SRAM_CORR_ERR_TEST wo — Test bit for SRAM correctable error interrupt.
0xE10 VBUS2APB_WRAP__VBUSP_APB__CSI2TX_V2_REGS_asf_fatal_nonfatal_select access not given reset 0x7F — The fatal or non-fatal interrupt register selects whether a fatal (asf_int_fatal) or non-fatal (asf_int_nonfatal) interrupt is triggered. If the bit of the event will be set to one then fatal interrupt (asf_int_fatal) will be triggered. Otherwise the non-fatal interrupt (asf_int_nonfatal) will be triggered.
  [6] ASF_INTEGRITY_ERR rw — Enable integrity error interrupt as fatal
  [5] ASF_PROTOCOL_ERR rw — Enable protocol error interrupt as fatal.
  [4] ASF_TRANS_TO_ERR rw — Enable transaction timeouts error interrupt as fatal.
  [3] ASF_CSR_ERR rw — Enable configuration and status registers error interrupt as fatal.
  [2] ASF_DAP_ERR rw — Enable data and address paths parity error interrupt as fatal.
  [1] ASF_SRAM_UNCORR_ERR rw — Enable SRAM uncorrectable error interrupt as fatal.
  [0] ASF_SRAM_CORR_ERR rw — Enable SRAM correctable error interrupt as fatal.
0xE20 VBUS2APB_WRAP__VBUSP_APB__CSI2TX_V2_REGS_asf_sram_corr_fault_status ro — Status register for SRAM correctable fault. These fields are updated whenever asf_sram_corr_fault input is active.
  [31:24] ASF_SRAM_CORR_FAULT_INST — Last SRAM instance that generated fault.
  [23:0] ASF_SRAM_CORR_FAULT_ADDR — Last SRAM address that generated fault.
0xE24 VBUS2APB_WRAP__VBUSP_APB__CSI2TX_V2_REGS_asf_sram_uncorr_fault_status ro — Status register for SRAM uncorrectable fault. These fields are updated whenever asf_sram_uncorr_fault input is active.
  [31:24] ASF_SRAM_UNCORR_FAULT_INST — Last SRAM instance that generated fault.
  [23:0] ASF_SRAM_UNCORR_FAULT_ADDR — Last SRAM address that generated fault.
0xE28 VBUS2APB_WRAP__VBUSP_APB__CSI2TX_V2_REGS_asf_sram_fault_stats access not given — Statistics register for SRAM faults. Note that this register clears when software writes to any field.
  [15:0] ASF_SRAM_FAULT_CORR_STATS — Count of number of correctable errors if implemented. Count value will saturate at 0xffff. (access R/W1TC)
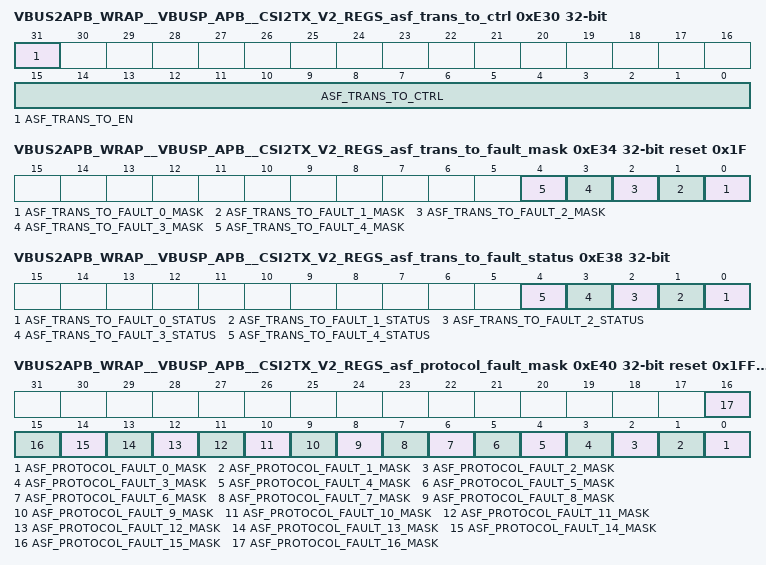
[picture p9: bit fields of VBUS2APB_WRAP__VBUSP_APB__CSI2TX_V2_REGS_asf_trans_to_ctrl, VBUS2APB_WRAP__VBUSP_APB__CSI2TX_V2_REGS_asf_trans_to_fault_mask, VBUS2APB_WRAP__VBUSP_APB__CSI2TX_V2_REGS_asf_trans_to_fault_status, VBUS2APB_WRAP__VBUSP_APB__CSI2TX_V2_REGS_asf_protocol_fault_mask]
0xE30 VBUS2APB_WRAP__VBUSP_APB__CSI2TX_V2_REGS_asf_trans_to_ctrl — Control register to configure the ASF transaction timeout monitors.
  [31] ASF_TRANS_TO_EN — Enable transaction timeout monitoring.
  [15:0] ASF_TRANS_TO_CTRL — Timer value to use for transaction timeout monitor.
0xE34 VBUS2APB_WRAP__VBUSP_APB__CSI2TX_V2_REGS_asf_trans_to_fault_mask reset 0x1F — Control register to mask out ASF transaction timeout faults from triggering interrupts. On reset, all bits are set to mask out all sources. Clear the corresponding bit to enable the interrupt source. The width of this field is parameterisable and the bit definitions are implementation specific.
  [n] ASF_TRANS_TO_FAULT_{n}_MASK (n=0..4) — Mask register for each ASF transaction timeout fault source.
0xE38 VBUS2APB_WRAP__VBUSP_APB__CSI2TX_V2_REGS_asf_trans_to_fault_status access not given — Status register for transaction timeouts fault. If a fault occurs the revelant status bit will be set to 1. Each bit can be cleared by software writing 1 to each bit.
  [n] ASF_TRANS_TO_FAULT_{n}_STATUS (n=0..4) — Status bits for transaction timeouts faults. (access R/W1TC)
0xE40 VBUS2APB_WRAP__VBUSP_APB__CSI2TX_V2_REGS_asf_protocol_fault_mask reset 0x1FFFF — Control register to mask out ASF Protocol faults from triggering interrupts. On reset, all bits are set to mask out all sources. Clear the corresponding bit to enable the interrupt source. The width of this field is parameterisable and the bit definitions are implementation specific.
  [n] ASF_PROTOCOL_FAULT_{n}_MASK (n=0..16) — Mask register for each ASF protocol fault source.
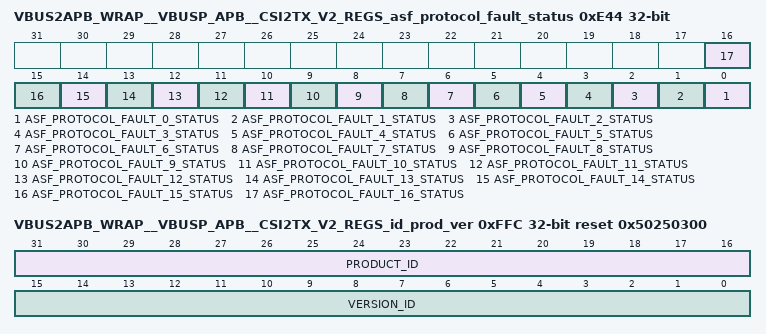
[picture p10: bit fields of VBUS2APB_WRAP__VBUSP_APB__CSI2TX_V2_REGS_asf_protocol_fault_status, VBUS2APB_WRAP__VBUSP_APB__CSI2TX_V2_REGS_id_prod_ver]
0xE44 VBUS2APB_WRAP__VBUSP_APB__CSI2TX_V2_REGS_asf_protocol_fault_status access not given — Status register for protocol faults. If a fault occurs the revelant status bit will be set to 1. Each bit can be cleared by software writing 1 to each bit
  [n] ASF_PROTOCOL_FAULT_{n}_STATUS (n=0..16) — Status bits for protocol faults. (access R/W1TC)
0xFFC VBUS2APB_WRAP__VBUSP_APB__CSI2TX_V2_REGS_id_prod_ver ro reset 0x50250300 — CSI-2 Transmitter Product ID and Version Register. This register is hard-coded in order to allow software to identify the product and its release version. The product ID will be fixed for all versions, while the version will be updated as new releases for the same product are made.
  [31:16] PRODUCT_ID — CSI-2 Transmitter Product Identification Number.
  [15:0] VERSION_ID — CSI-2 Transmitter Product Version Number.
